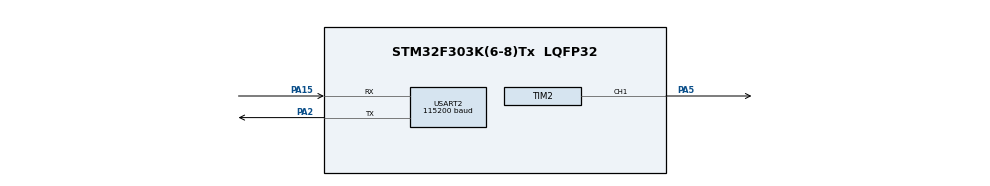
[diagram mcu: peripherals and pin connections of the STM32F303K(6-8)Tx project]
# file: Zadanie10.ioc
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Dma.Request0=USART2_RX
Dma.Request1=USART2_TX
Dma.USART2_RX.0.Direction=DMA_PERIPH_TO_MEMORY
Dma.USART2_RX.0.Instance=DMA1_Channel6
Dma.USART2_RX.0.MemDataAlignment=DMA_MDATAALIGN_BYTE
Dma.USART2_RX.0.MemInc=DMA_MINC_ENABLE
Dma.USART2_RX.0.Mode=DMA_CIRCULAR
Dma.USART2_RX.0.PeriphDataAlignment=DMA_PDATAALIGN_BYTE
Dma.USART2_RX.0.PeriphInc=DMA_PINC_DISABLE
Dma.USART2_RX.0.Priority=DMA_PRIORITY_LOW
Dma.USART2_TX.1.Direction=DMA_MEMORY_TO_PERIPH
Dma.USART2_TX.1.Instance=DMA1_Channel7
Dma.USART2_TX.1.MemDataAlignment=DMA_MDATAALIGN_BYTE
Dma.USART2_TX.1.MemInc=DMA_MINC_ENABLE
Dma.USART2_TX.1.Mode=DMA_NORMAL
Dma.USART2_TX.1.PeriphDataAlignment=DMA_PDATAALIGN_BYTE
Dma.USART2_TX.1.PeriphInc=DMA_PINC_DISABLE
Dma.USART2_TX.1.Priority=DMA_PRIORITY_LOW
Mcu.Family=STM32F3
Mcu.Name=STM32F303K(6-8)Tx
Mcu.Package=LQFP32
NVIC.DMA1_Channel6_IRQn=true\:0\:0\:false\:false\:true\:false\:true
NVIC.DMA1_Channel7_IRQn=true\:0\:0\:false\:false\:true\:false\:true
NVIC.PriorityGroup=NVIC_PRIORITYGROUP_4
NVIC.TIM3_IRQn=true\:0\:0\:false\:false\:true\:true\:true
NVIC.USART2_IRQn=true\:0\:0\:false\:false\:true\:true\:true
PA15.Mode=Asynchronous
PA15.Signal=USART2_RX
PA2.Mode=Asynchronous
PA2.Signal=USART2_TX
PA5.Signal=S_TIM2_CH1_ETR
ProjectManager.HeapSize=0x200
ProjectManager.StackSize=0x400
ProjectManager.TargetToolchain=STM32CubeIDE
RCC.AHBFreq_Value=8000000
RCC.APB1Freq_Value=8000000
RCC.APB2Freq_Value=8000000
RCC.CortexFreq_Value=8000000
RCC.HSE_VALUE=8000000
RCC.HSI_VALUE=8000000
RCC.SYSCLKFreq_VALUE=8000000
SH.S_TIM2_CH1_ETR.0=TIM2_CH1,PWM Generation1 CH1
TIM2.Channel-PWM\ Generation1\ CH1=TIM_CHANNEL_1
TIM2.Period=99
TIM2.Prescaler=799
TIM3.Channel-Output\ Compare1\ No\ Output=TIM_CHANNEL_1
TIM3.OCMode_1=TIM_OCMODE_ACTIVE
TIM3.Period=9
TIM3.Prescaler=7999
USART2.BaudRate=115200
USART2.VirtualMode-Asynchronous=VM_ASYNC
VP_TIM2_VS_ClockSourceINT.Mode=Internal
VP_TIM3_VS_ClockSourceINT.Mode=Internal
VP_TIM3_VS_no_output1.Mode=Output Compare1 No Output
board=custom

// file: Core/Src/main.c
/* USER CODE BEGIN Header */
/**
  ******************************************************************************
  * @file           : main.c
  * @brief          : Main program body
  ******************************************************************************
  * @attention
  *
  * <h2><center>&copy; Copyright (c) 2020 STMicroelectronics.
  * All rights reserved.</center></h2>
  *
  * This software component is licensed by ST under BSD 3-Clause license,
  * the "License"; You may not use this file except in compliance with the
  * License. You may obtain a copy of the License at:
  *                        opensource.org/licenses/BSD-3-Clause
  *
  ******************************************************************************
  */
/* USER CODE END Header */

#include "main.h"
#include "dma.h"
#include "tim.h"
#include "usart.h"
#include "gpio.h"
#include <stdio.h>
#include <string.h>
/* USER CODE BEGIN Includes */
void proccesDmaData(const uint8_t* data, uint16_t len);
/* USER CODE END Includes */

/* USER CODE BEGIN PV */
int start = 0;
static char message[34]= "";
int autoON = 1;
int PWM = 100;
int enteredmode = 1;
/* USER CODE END PV */

void SystemClock_Config(void);

int main(void)
{

  /* MCU Configuration--------------------------------------------------------*/

  /* Reset of all peripherals, Initializes the Flash interface and the Systick. */

  LL_APB2_GRP1_EnableClock(LL_APB2_GRP1_PERIPH_SYSCFG);
  LL_APB1_GRP1_EnableClock(LL_APB1_GRP1_PERIPH_PWR);

  NVIC_SetPriorityGrouping(NVIC_PRIORITYGROUP_4);

  /* System interrupt init*/

  /* Configure the system clock */
  SystemClock_Config();

  /* Initialize all configured peripherals */
  MX_GPIO_Init();
  MX_DMA_Init();
  MX_TIM2_Init();
  MX_TIM3_Init();
  MX_USART2_UART_Init();
  /* USER CODE BEGIN 2 */

  	  //type your code here:
  USART2_RegisterCallback(proccesDmaData);
  LL_TIM_CC_EnableChannel(TIM2, LL_TIM_CHANNEL_CH1);
  LL_TIM_EnableIT_UPDATE(TIM2);
  LL_TIM_EnableCounter(TIM2);
  LL_TIM_EnableIT_UPDATE(TIM3);
  LL_TIM_EnableCounter(TIM3);

  /* USER CODE END 2 */

  /* Infinite loop */
  while (1)
  {
	#if POLLING
		USART2_CheckDmaReception();
		LL_mDelay(10);
	#else
		USART2_PutBuffer(tx_data, sizeof(tx_data));
		LL_mDelay(1000);
	#endif
  }
}

void setDutyCycle(uint8_t D)
{
	TIM2->CCR1 = D;
}
void SystemClock_Config(void)
{
  LL_FLASH_SetLatency(LL_FLASH_LATENCY_0);

  if(LL_FLASH_GetLatency() != LL_FLASH_LATENCY_0)
  {
  Error_Handler();
  }
  LL_RCC_HSI_Enable();

   /* Wait till HSI is ready */
  while(LL_RCC_HSI_IsReady() != 1)
  {

  }
  LL_RCC_HSI_SetCalibTrimming(16);
  LL_RCC_SetAHBPrescaler(LL_RCC_SYSCLK_DIV_1);
  LL_RCC_SetAPB1Prescaler(LL_RCC_APB1_DIV_1);
  LL_RCC_SetAPB2Prescaler(LL_RCC_APB1_DIV_1);
  LL_RCC_SetSysClkSource(LL_RCC_SYS_CLKSOURCE_HSI);

   /* Wait till System clock is ready */
  while(LL_RCC_GetSysClkSource() != LL_RCC_SYS_CLKSOURCE_STATUS_HSI)
  {

  }
  LL_Init1msTick(8000000);
  LL_SetSystemCoreClock(8000000);
}

/* USER CODE BEGIN 4 */
void proccesDmaData(const uint8_t* data, uint16_t len)
{
    /* Process received data */

        // type your algorithm here:

    for(uint8_t i = 0; i < len; i++)
    {

        if ((*(data+i) == '$') && (start))
        {
            CompareMessage();
            memset(message,0,sizeof(message));
            start = 0;
            break;
        }
        else if(*(data+i) == '$')
        {
            start = 1;
            break;
        }

        if((start >= 1) && (start <= 34))
        {
            message[start-1]= *(data+i);
            start++;
        }
        else
        {
        	start = 0;
        	memset(message,0,sizeof(message));
        }

    }
}

void CompareMessage()
{

	if(strcmp(message, "auto") == 0)
    {
    	autoON = 1;
    	//PWM = 100;
    	enteredmode = 1;
    }
	if(strcmp(message, "manual") == 0)
    {
    	autoON = 0;
    	enteredmode = 1;
    }

    if(autoON == 0)
    {
    	if(strncmp(message, "PWM",3) == 0)
    	{
    		PWM = atoi(message+3);
      		if (PWM > 99)
    		{
    			PWM = 100;
    		}
      		enteredmode = 0;
    	}

    }

}

/* USER CODE END 4 */

void Error_Handler(void)
{
}

/************************ (C) COPYRIGHT STMicroelectronics *****END OF FILE****/
